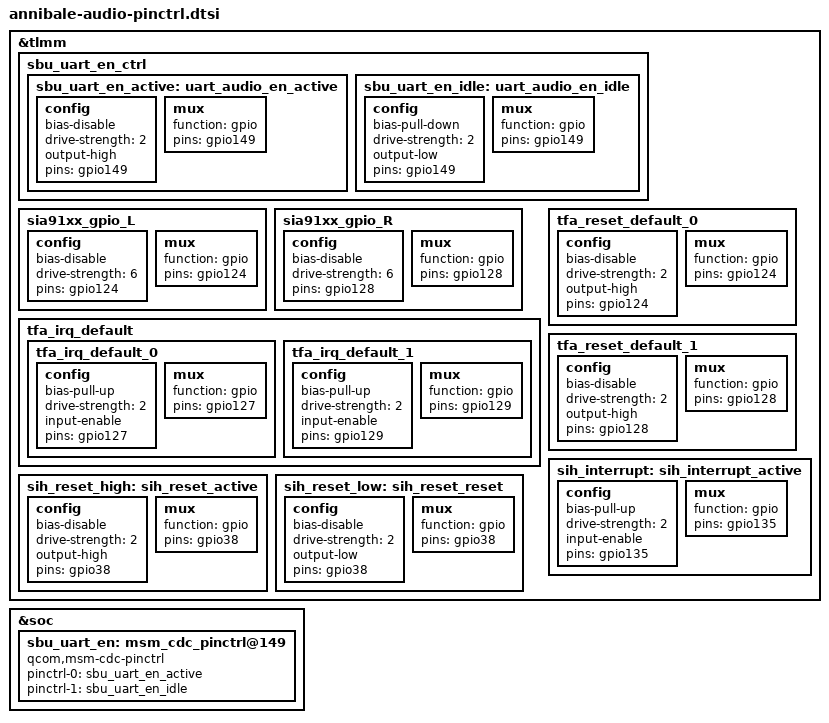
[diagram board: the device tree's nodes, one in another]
&tlmm {
    sbu_uart_en_ctrl {
        sbu_uart_en_active: uart_audio_en_active {
            config {
                bias-disable;
                drive-strength = <2>; /* 2 MA */
                output-high;
                pins = "gpio149";
            };
            mux {
                function = "gpio";
                pins = "gpio149";
            };
        };
        sbu_uart_en_idle: uart_audio_en_idle {
            config {
                bias-pull-down;
                drive-strength = <2>; /* 2 MA */
                output-low;
                pins = "gpio149";
            };
            mux {
                function = "gpio";
                pins = "gpio149";
            };
        };
    };

    sia91xx_gpio_L: sia91xx_gpio_L {
        config {
            bias-disable;
            drive-strength = <6>;
            pins = "gpio124";
        };
        mux {
            function = "gpio";
            pins = "gpio124";
        };
    };

    sia91xx_gpio_R: sia91xx_gpio_R {
        config {
            bias-disable;
            drive-strength = <6>;
            pins = "gpio128";
        };
        mux {
            function = "gpio";
            pins = "gpio128";
        };
    };

    tfa_irq_default {
        tfa_irq_default_0: tfa_irq_default_0 {
            config {
                bias-pull-up;
                drive-strength = <2>;
                input-enable;
                pins = "gpio127"; 
            };
            mux {
                function = "gpio";
                pins = "gpio127";
            };
        };
        tfa_irq_default_1: tfa_irq_default_1 {
            config {
                bias-pull-up;
                drive-strength = <2>;
                input-enable;
                pins = "gpio129";
            };
            mux {
                function = "gpio";
                pins = "gpio129";
            };
        };
    };

    tfa_reset_default_0: tfa_reset_default_0 {
        config {
            bias-disable;
            drive-strength = <2>;
            output-high;
            pins = "gpio124";
        };
        mux {
            function = "gpio";
            pins = "gpio124";
        };
    };

    tfa_reset_default_1: tfa_reset_default_1 {
        config {
            bias-disable;
            drive-strength = <2>;
            output-high;
            pins = "gpio128";
        };
        mux {
            function = "gpio";
            pins = "gpio128";
        };
    };

    sih_interrupt: sih_interrupt_active {
        config {
            bias-pull-up;
            drive-strength = <2>;
            input-enable;
            pins = "gpio135"; 
        };
        mux {
            function = "gpio";
            pins = "gpio135";
        };
    };

    sih_reset_high: sih_reset_active {
        config {
            bias-disable;
            drive-strength = <2>;
            output-high;
            pins = "gpio38";
        };
        mux {
            function = "gpio";
            pins = "gpio38";
        };
    };

    sih_reset_low: sih_reset_reset {
        config {
            bias-disable;
            drive-strength = <2>;
            output-low;
            pins = "gpio38";
        };
        mux {
            function = "gpio";
            pins = "gpio38";
        };
    };
};

&soc {
    sbu_uart_en: msm_cdc_pinctrl@149 {
        #gpio-cells = <0>;
        compatible = "qcom,msm-cdc-pinctrl";
        pinctrl-0 = <&sbu_uart_en_active>;
        pinctrl-1 = <&sbu_uart_en_idle>;
        pinctrl-names = "aud_active", "aud_sleep";
    };
};
